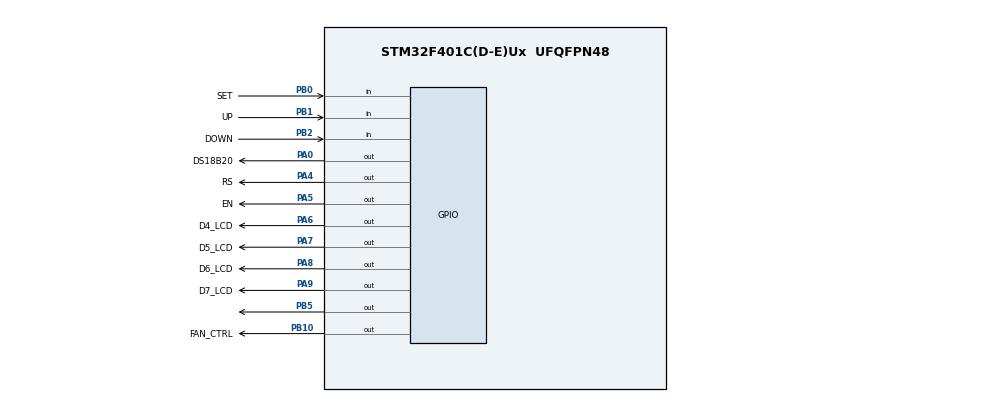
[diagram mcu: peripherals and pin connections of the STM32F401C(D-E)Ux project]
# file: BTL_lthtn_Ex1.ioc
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Mcu.Family=STM32F4
Mcu.Name=STM32F401C(D-E)Ux
Mcu.Package=UFQFPN48
NVIC.PriorityGroup=NVIC_PRIORITYGROUP_4
PA0-WKUP.GPIO_Label=DS18B20
PA0-WKUP.GPIO_ModeDefaultOutputPP=GPIO_MODE_OUTPUT_OD
PA0-WKUP.GPIO_PuPd=GPIO_PULLUP
PA0-WKUP.Signal=GPIO_Output
PA4.GPIO_Label=RS
PA4.Signal=GPIO_Output
PA5.GPIO_Label=EN
PA5.Signal=GPIO_Output
PA6.GPIO_Label=D4_LCD
PA6.Signal=GPIO_Output
PA7.GPIO_Label=D5_LCD
PA7.Signal=GPIO_Output
PA8.GPIO_Label=D6_LCD
PA8.Signal=GPIO_Output
PA9.GPIO_Label=D7_LCD
PA9.Signal=GPIO_Output
PB0.GPIO_Label=SET
PB0.GPIO_PuPd=GPIO_PULLUP
PB0.Signal=GPIO_Input
PB1.GPIO_Label=UP
PB1.GPIO_PuPd=GPIO_PULLUP
PB1.Signal=GPIO_Input
PB10.GPIO_Label=FAN_CTRL
PB10.Signal=GPIO_Output
PB2.GPIO_Label=DOWN
PB2.GPIO_PuPd=GPIO_PULLUP
PB2.Signal=GPIO_Input
PB5.Signal=GPIO_Output
ProjectManager.HeapSize=0x200
ProjectManager.StackSize=0x400
ProjectManager.TargetToolchain=STM32CubeIDE
RCC.AHBFreq_Value=16000000
RCC.APB1Freq_Value=16000000
RCC.APB2Freq_Value=16000000
RCC.CortexFreq_Value=16000000
RCC.HSE_VALUE=25000000
RCC.HSI_VALUE=16000000
RCC.LSE_VALUE=32768
RCC.SYSCLKFreq_VALUE=16000000
RCC.VCOOutputFreq_Value=192000000
TIM2.Prescaler=15
VP_TIM2_VS_ClockSourceINT.Mode=Internal
board=custom

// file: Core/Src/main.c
/* USER CODE BEGIN Header */
/**
  ******************************************************************************
  * @file           : main.c
  * @brief          : Main program body
  ******************************************************************************
  * @attention
  *
  * Copyright (c) 2026 STMicroelectronics.
  * All rights reserved.
  *
  * This software is licensed under terms that can be found in the LICENSE file
  * in the root directory of this software component.
  * If no LICENSE file comes with this software, it is provided AS-IS.
  *
  ******************************************************************************
  */
/* USER CODE END Header */
#include "main.h"

/* USER CODE BEGIN Includes */
#include "app_thermostat.h"
/* USER CODE END Includes */

void SystemClock_Config(void);
static void MX_GPIO_Init(void);
static void MX_TIM2_Init(void);

int main(void)
{

  /* MCU Configuration--------------------------------------------------------*/

  /* Reset of all peripherals, Initializes the Flash interface and the Systick. */
  LL_APB2_GRP1_EnableClock(LL_APB2_GRP1_PERIPH_SYSCFG);
  LL_APB1_GRP1_EnableClock(LL_APB1_GRP1_PERIPH_PWR);

  /* System interrupt init*/
  NVIC_SetPriorityGrouping(NVIC_PRIORITYGROUP_4);

  /* SysTick_IRQn interrupt configuration */
  NVIC_SetPriority(SysTick_IRQn, NVIC_EncodePriority(NVIC_GetPriorityGrouping(),15, 0));

  /* Configure the system clock */
  SystemClock_Config();

  /* USER CODE BEGIN SysInit */
  LL_SYSTICK_EnableIT();
  /* USER CODE END SysInit */

  /* Initialize all configured peripherals */
  MX_GPIO_Init();
  MX_TIM2_Init();
  /* USER CODE BEGIN 2 */
  APP_Thermostat_Init();
  /* USER CODE END 2 */

  /* Infinite loop */
  while (1)
  {

    /* USER CODE BEGIN 3 */
	 APP_Thermostat_Run();
  }
  /* USER CODE END 3 */
}

void SystemClock_Config(void)
{
  LL_FLASH_SetLatency(LL_FLASH_LATENCY_0);
  while(LL_FLASH_GetLatency()!= LL_FLASH_LATENCY_0)
  {
  }
  LL_PWR_SetRegulVoltageScaling(LL_PWR_REGU_VOLTAGE_SCALE2);
  LL_RCC_HSI_SetCalibTrimming(16);
  LL_RCC_HSI_Enable();

   /* Wait till HSI is ready */
  while(LL_RCC_HSI_IsReady() != 1)
  {

  }
  LL_RCC_SetAHBPrescaler(LL_RCC_SYSCLK_DIV_1);
  LL_RCC_SetAPB1Prescaler(LL_RCC_APB1_DIV_1);
  LL_RCC_SetAPB2Prescaler(LL_RCC_APB2_DIV_1);
  LL_RCC_SetSysClkSource(LL_RCC_SYS_CLKSOURCE_HSI);

   /* Wait till System clock is ready */
  while(LL_RCC_GetSysClkSource() != LL_RCC_SYS_CLKSOURCE_STATUS_HSI)
  {

  }
  LL_Init1msTick(16000000);
  LL_SetSystemCoreClock(16000000);
  LL_RCC_SetTIMPrescaler(LL_RCC_TIM_PRESCALER_TWICE);
}

static void MX_TIM2_Init(void)
{

  LL_TIM_InitTypeDef TIM_InitStruct = {0};

  /* Peripheral clock enable */
  LL_APB1_GRP1_EnableClock(LL_APB1_GRP1_PERIPH_TIM2);

  TIM_InitStruct.Prescaler = 15;
  TIM_InitStruct.CounterMode = LL_TIM_COUNTERMODE_UP;
  TIM_InitStruct.Autoreload = 4294967295;
  TIM_InitStruct.ClockDivision = LL_TIM_CLOCKDIVISION_DIV1;
  LL_TIM_Init(TIM2, &TIM_InitStruct);
  LL_TIM_DisableARRPreload(TIM2);
  LL_TIM_SetClockSource(TIM2, LL_TIM_CLOCKSOURCE_INTERNAL);
  LL_TIM_SetTriggerOutput(TIM2, LL_TIM_TRGO_RESET);
  LL_TIM_DisableMasterSlaveMode(TIM2);

}

static void MX_GPIO_Init(void)
{
  LL_GPIO_InitTypeDef GPIO_InitStruct = {0};

  /* GPIO Ports Clock Enable */
  LL_AHB1_GRP1_EnableClock(LL_AHB1_GRP1_PERIPH_GPIOA);
  LL_AHB1_GRP1_EnableClock(LL_AHB1_GRP1_PERIPH_GPIOB);

  /**/
  LL_GPIO_ResetOutputPin(GPIOA, DS18B20_Pin|RS_Pin|EN_Pin|D4_LCD_Pin
                          |D5_LCD_Pin|D6_LCD_Pin|D7_LCD_Pin);

  /**/
  LL_GPIO_ResetOutputPin(GPIOB, FAN_CTRL_Pin|LL_GPIO_PIN_5);

  /**/
  GPIO_InitStruct.Pin = DS18B20_Pin;
  GPIO_InitStruct.Mode = LL_GPIO_MODE_OUTPUT;
  GPIO_InitStruct.Speed = LL_GPIO_SPEED_FREQ_LOW;
  GPIO_InitStruct.OutputType = LL_GPIO_OUTPUT_OPENDRAIN;
  GPIO_InitStruct.Pull = LL_GPIO_PULL_UP;
  LL_GPIO_Init(DS18B20_GPIO_Port, &GPIO_InitStruct);

  /**/
  GPIO_InitStruct.Pin = RS_Pin|EN_Pin|D4_LCD_Pin|D5_LCD_Pin
                          |D6_LCD_Pin|D7_LCD_Pin;
  GPIO_InitStruct.Mode = LL_GPIO_MODE_OUTPUT;
  GPIO_InitStruct.Speed = LL_GPIO_SPEED_FREQ_LOW;
  GPIO_InitStruct.OutputType = LL_GPIO_OUTPUT_PUSHPULL;
  GPIO_InitStruct.Pull = LL_GPIO_PULL_NO;
  LL_GPIO_Init(GPIOA, &GPIO_InitStruct);

  /**/
  GPIO_InitStruct.Pin = SET_Pin|UP_Pin|DOWN_Pin;
  GPIO_InitStruct.Mode = LL_GPIO_MODE_INPUT;
  GPIO_InitStruct.Pull = LL_GPIO_PULL_UP;
  LL_GPIO_Init(GPIOB, &GPIO_InitStruct);

  /**/
  GPIO_InitStruct.Pin = FAN_CTRL_Pin|LL_GPIO_PIN_5;
  GPIO_InitStruct.Mode = LL_GPIO_MODE_OUTPUT;
  GPIO_InitStruct.Speed = LL_GPIO_SPEED_FREQ_LOW;
  GPIO_InitStruct.OutputType = LL_GPIO_OUTPUT_PUSHPULL;
  GPIO_InitStruct.Pull = LL_GPIO_PULL_NO;
  LL_GPIO_Init(GPIOB, &GPIO_InitStruct);

}

void Error_Handler(void)
{
  __disable_irq();
  while (1)
  {
  }
}
